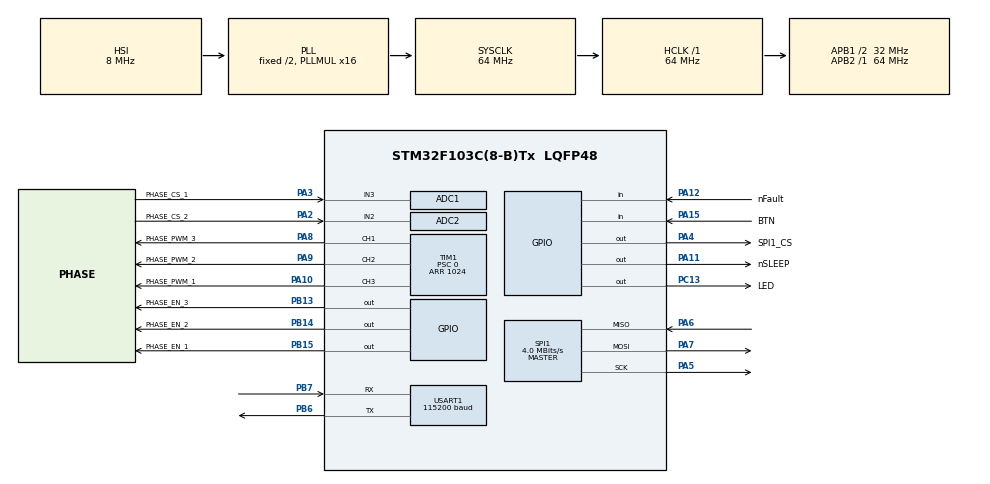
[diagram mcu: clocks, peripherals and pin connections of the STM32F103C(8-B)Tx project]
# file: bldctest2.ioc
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ADC1.Channel-4\#ChannelRegularConversion=ADC_CHANNEL_3
ADC1.Mode=ADC_DUALMODE_REGSIMULT_INJECSIMULT
ADC1.NbrOfConversionFlag=1
ADC1.Rank-4\#ChannelRegularConversion=1
ADC1.SamplingTime-4\#ChannelRegularConversion=ADC_SAMPLETIME_7CYCLES_5
ADC1.master=1
ADC2.Channel-0\#ChannelRegularConversion=ADC_CHANNEL_2
ADC2.Mode=ADC_DUALMODE_REGSIMULT_INJECSIMULT
ADC2.NbrOfConversionFlag=1
ADC2.Rank-0\#ChannelRegularConversion=1
ADC2.SamplingTime-0\#ChannelRegularConversion=ADC_SAMPLETIME_7CYCLES_5
Dma.ADC1.1.Direction=DMA_PERIPH_TO_MEMORY
Dma.ADC1.1.Instance=DMA1_Channel1
Dma.ADC1.1.MemDataAlignment=DMA_MDATAALIGN_WORD
Dma.ADC1.1.MemInc=DMA_MINC_ENABLE
Dma.ADC1.1.Mode=DMA_NORMAL
Dma.ADC1.1.PeriphDataAlignment=DMA_PDATAALIGN_WORD
Dma.ADC1.1.PeriphInc=DMA_PINC_DISABLE
Dma.ADC1.1.Priority=DMA_PRIORITY_LOW
Dma.Request0=USART1_TX
Dma.Request1=ADC1
Dma.USART1_TX.0.Direction=DMA_MEMORY_TO_PERIPH
Dma.USART1_TX.0.Instance=DMA1_Channel4
Dma.USART1_TX.0.MemDataAlignment=DMA_MDATAALIGN_BYTE
Dma.USART1_TX.0.MemInc=DMA_MINC_ENABLE
Dma.USART1_TX.0.Mode=DMA_NORMAL
Dma.USART1_TX.0.PeriphDataAlignment=DMA_PDATAALIGN_BYTE
Dma.USART1_TX.0.PeriphInc=DMA_PINC_DISABLE
Dma.USART1_TX.0.Priority=DMA_PRIORITY_LOW
Mcu.Family=STM32F1
Mcu.Name=STM32F103C(8-B)Tx
Mcu.Package=LQFP48
NVIC.DMA1_Channel1_IRQn=true\:0\:0\:false\:false\:true\:false\:true
NVIC.DMA1_Channel4_IRQn=true\:0\:0\:false\:false\:true\:false\:true
NVIC.PriorityGroup=NVIC_PRIORITYGROUP_4
NVIC.SPI1_IRQn=true\:1\:0\:true\:false\:true\:true\:true
NVIC.TIM1_UP_IRQn=true\:1\:0\:true\:false\:true\:true\:true
PA1.GPIO_Label=PHASE_CS_3
PA1.Signal=ADCx_IN1
PA10.GPIO_Label=PHASE_PWM_1
PA10.Signal=S_TIM1_CH3
PA11.GPIO_Label=nSLEEP
PA11.Signal=GPIO_Output
PA12.GPIO_Label=nFault
PA12.Signal=GPIO_Input
PA13.Mode=Serial_Wire
PA13.Signal=SYS_JTMS-SWDIO
PA14.Mode=Serial_Wire
PA14.Signal=SYS_JTCK-SWCLK
PA15.GPIO_Label=BTN
PA15.GPIO_PuPd=GPIO_PULLUP
PA15.Signal=GPIO_Input
PA2.GPIO_Label=PHASE_CS_2
PA2.Signal=ADCx_IN2
PA3.GPIO_Label=PHASE_CS_1
PA3.Signal=ADCx_IN3
PA4.GPIO_Label=SPI1_CS
PA4.PinState=GPIO_PIN_SET
PA4.Signal=GPIO_Output
PA5.Mode=Full_Duplex_Master
PA5.Signal=SPI1_SCK
PA6.Mode=Full_Duplex_Master
PA6.Signal=SPI1_MISO
PA7.Mode=Full_Duplex_Master
PA7.Signal=SPI1_MOSI
PA8.GPIO_Label=PHASE_PWM_3
PA8.Signal=S_TIM1_CH1
PA9.GPIO_Label=PHASE_PWM_2
PA9.Signal=S_TIM1_CH2
PB1.GPIO_Label=BATT_SENSE
PB1.Signal=ADCx_IN9
PB13.GPIO_Label=PHASE_EN_3
PB13.Signal=GPIO_Output
PB14.GPIO_Label=PHASE_EN_2
PB14.Signal=GPIO_Output
PB15.GPIO_Label=PHASE_EN_1
PB15.Signal=GPIO_Output
PB6.Mode=Asynchronous
PB6.Signal=USART1_TX
PB7.Mode=Asynchronous
PB7.Signal=USART1_RX
PC13-TAMPER-RTC.GPIO_Label=LED
PC13-TAMPER-RTC.PinState=GPIO_PIN_SET
PC13-TAMPER-RTC.Signal=GPIO_Output
ProjectManager.HeapSize=0x200
ProjectManager.StackSize=0x400
ProjectManager.TargetToolchain=STM32CubeIDE
RCC.ADCPresc=RCC_ADCPCLK2_DIV6
RCC.AHBFreq_Value=64000000
RCC.APB1CLKDivider=RCC_HCLK_DIV2
RCC.APB1Freq_Value=32000000
RCC.APB1TimFreq_Value=64000000
RCC.APB2Freq_Value=64000000
RCC.APB2TimFreq_Value=64000000
RCC.HCLKFreq_Value=64000000
RCC.PLLMUL=RCC_PLL_MUL16
RCC.SYSCLKFreq_VALUE=64000000
RCC.SYSCLKSource=RCC_SYSCLKSOURCE_PLLCLK
RCC.USBFreq_Value=64000000
SH.ADCx_IN1.0=ADC1_IN1
SH.ADCx_IN2.0=ADC1_IN2
SH.ADCx_IN2.1=ADC2_IN2,IN2
SH.ADCx_IN3.0=ADC1_IN3,IN3
SH.ADCx_IN9.0=ADC1_IN9
SH.S_TIM1_CH1.0=TIM1_CH1,PWM Generation1 CH1
SH.S_TIM1_CH2.0=TIM1_CH2,PWM Generation2 CH2
SH.S_TIM1_CH3.0=TIM1_CH3,PWM Generation3 CH3
SPI1.BaudRatePrescaler=SPI_BAUDRATEPRESCALER_16
SPI1.CLKPhase=SPI_PHASE_2EDGE
SPI1.CalculateBaudRate=4.0 MBits/s
SPI1.DataSize=SPI_DATASIZE_16BIT
SPI1.Direction=SPI_DIRECTION_2LINES
SPI1.Mode=SPI_MODE_MASTER
SPI1.VirtualType=VM_MASTER
TIM1.AutoReloadPreload=TIM_AUTORELOAD_PRELOAD_ENABLE
TIM1.Channel-PWM\ Generation1\ CH1=TIM_CHANNEL_1
TIM1.Channel-PWM\ Generation2\ CH2=TIM_CHANNEL_2
TIM1.Channel-PWM\ Generation3\ CH3=TIM_CHANNEL_3
TIM1.CounterMode=TIM_COUNTERMODE_CENTERALIGNED2
TIM1.OCIdleState_1=TIM_OCIDLESTATE_RESET
TIM1.OCIdleState_2=TIM_OCIDLESTATE_RESET
TIM1.OCIdleState_3=TIM_OCIDLESTATE_RESET
TIM1.OCMode_PWM-PWM\ Generation1\ CH1=TIM_OCMODE_PWM1
TIM1.OCMode_PWM-PWM\ Generation2\ CH2=TIM_OCMODE_PWM1
TIM1.OCMode_PWM-PWM\ Generation3\ CH3=TIM_OCMODE_PWM1
TIM1.Period=1024
TIM1.Prescaler=0
TIM1.RepetitionCounter=3
TIM3.Period=10
TIM3.Prescaler=225
TIM3.TIM_MasterOutputTrigger=TIM_TRGO_UPDATE
USART1.BaudRate=115200
USART1.Mode=MODE_TX_RX
USART1.VirtualMode=VM_ASYNC
VP_TIM1_VS_ClockSourceINT.Mode=Internal
VP_TIM3_VS_ClockSourceINT.Mode=Internal
board=custom

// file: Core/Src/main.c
/* USER CODE BEGIN Header */
/**
  ******************************************************************************
  * @file           : main.c
  * @brief          : Main program body
  ******************************************************************************
  * @attention
  *
  * <h2><center>&copy; Copyright (c) 2020 STMicroelectronics.
  * All rights reserved.</center></h2>
  *
  * This software component is licensed by ST under BSD 3-Clause license,
  * the "License"; You may not use this file except in compliance with the
  * License. You may obtain a copy of the License at:
  *                        opensource.org/licenses/BSD-3-Clause
  *
  ******************************************************************************
  */
/* USER CODE END Header */

#include "main.h"

/* USER CODE BEGIN Includes */
#include "app/main.hpp"
#include "string.h"
/* USER CODE END Includes */

ADC_HandleTypeDef hadc1;
ADC_HandleTypeDef hadc2;
DMA_HandleTypeDef hdma_adc1;

SPI_HandleTypeDef hspi1;

TIM_HandleTypeDef htim1;
TIM_HandleTypeDef htim3;

UART_HandleTypeDef huart1;
DMA_HandleTypeDef hdma_usart1_tx;

void SystemClock_Config(void);
static void MX_GPIO_Init(void);
static void MX_DMA_Init(void);
static void MX_ADC1_Init(void);
static void MX_SPI1_Init(void);
static void MX_TIM1_Init(void);
static void MX_TIM3_Init(void);
static void MX_USART1_UART_Init(void);
static void MX_ADC2_Init(void);

int main(void)
{

  /* MCU Configuration--------------------------------------------------------*/

  /* Reset of all peripherals, Initializes the Flash interface and the Systick. */
  HAL_Init();

  /* Configure the system clock */
  SystemClock_Config();

  /* Initialize all configured peripherals */
  MX_GPIO_Init();
  MX_DMA_Init();
  MX_ADC1_Init();
  MX_SPI1_Init();
  MX_TIM1_Init();
  MX_TIM3_Init();
  MX_USART1_UART_Init();
  MX_ADC2_Init();
  /* USER CODE BEGIN 2 */
  //const char msg[] = "hello!";

  //__HAL_SPI_ENABLE_IT(&hspi1, SPI_IT_RXNE);

  /* USER CODE END 2 */

  /* Infinite loop */
  /* USER CODE BEGIN WHILE */

  main_cpp();

  while (1)
  {
	/*huart1.Instance->CR3 |= USART_CR3_DMAT;
	HAL_DMA_Start_IT(&hdma_usart1_tx, (uint32_t) &msg, (uint32_t) &huart1.Instance->DR, strlen(msg));

	HAL_Delay(1000);*/
    /* USER CODE END WHILE */

  }
}

void SystemClock_Config(void)
{
  RCC_OscInitTypeDef RCC_OscInitStruct = {0};
  RCC_ClkInitTypeDef RCC_ClkInitStruct = {0};
  RCC_PeriphCLKInitTypeDef PeriphClkInit = {0};

  /** Initializes the CPU, AHB and APB busses clocks
  */
  RCC_OscInitStruct.OscillatorType = RCC_OSCILLATORTYPE_HSI;
  RCC_OscInitStruct.HSIState = RCC_HSI_ON;
  RCC_OscInitStruct.HSICalibrationValue = RCC_HSICALIBRATION_DEFAULT;
  RCC_OscInitStruct.PLL.PLLState = RCC_PLL_ON;
  RCC_OscInitStruct.PLL.PLLSource = RCC_PLLSOURCE_HSI_DIV2;
  RCC_OscInitStruct.PLL.PLLMUL = RCC_PLL_MUL16;
  if (HAL_RCC_OscConfig(&RCC_OscInitStruct) != HAL_OK)
  {
    Error_Handler();
  }
  /** Initializes the CPU, AHB and APB busses clocks
  */
  RCC_ClkInitStruct.ClockType = RCC_CLOCKTYPE_HCLK|RCC_CLOCKTYPE_SYSCLK
                              |RCC_CLOCKTYPE_PCLK1|RCC_CLOCKTYPE_PCLK2;
  RCC_ClkInitStruct.SYSCLKSource = RCC_SYSCLKSOURCE_PLLCLK;
  RCC_ClkInitStruct.AHBCLKDivider = RCC_SYSCLK_DIV1;
  RCC_ClkInitStruct.APB1CLKDivider = RCC_HCLK_DIV2;
  RCC_ClkInitStruct.APB2CLKDivider = RCC_HCLK_DIV1;

  if (HAL_RCC_ClockConfig(&RCC_ClkInitStruct, FLASH_LATENCY_2) != HAL_OK)
  {
    Error_Handler();
  }
  PeriphClkInit.PeriphClockSelection = RCC_PERIPHCLK_ADC;
  PeriphClkInit.AdcClockSelection = RCC_ADCPCLK2_DIV6;
  if (HAL_RCCEx_PeriphCLKConfig(&PeriphClkInit) != HAL_OK)
  {
    Error_Handler();
  }
}

static void MX_ADC1_Init(void)
{

  ADC_MultiModeTypeDef multimode = {0};
  ADC_ChannelConfTypeDef sConfig = {0};

  /** Common config
  */
  hadc1.Instance = ADC1;
  hadc1.Init.ScanConvMode = ADC_SCAN_DISABLE;
  hadc1.Init.ContinuousConvMode = DISABLE;
  hadc1.Init.DiscontinuousConvMode = DISABLE;
  hadc1.Init.ExternalTrigConv = ADC_SOFTWARE_START;
  hadc1.Init.DataAlign = ADC_DATAALIGN_RIGHT;
  hadc1.Init.NbrOfConversion = 1;
  if (HAL_ADC_Init(&hadc1) != HAL_OK)
  {
    Error_Handler();
  }
  /** Configure the ADC multi-mode
  */
  multimode.Mode = ADC_DUALMODE_REGSIMULT_INJECSIMULT;
  if (HAL_ADCEx_MultiModeConfigChannel(&hadc1, &multimode) != HAL_OK)
  {
    Error_Handler();
  }
  /** Configure Regular Channel
  */
  sConfig.Channel = ADC_CHANNEL_3;
  sConfig.Rank = ADC_REGULAR_RANK_1;
  sConfig.SamplingTime = ADC_SAMPLETIME_7CYCLES_5;
  if (HAL_ADC_ConfigChannel(&hadc1, &sConfig) != HAL_OK)
  {
    Error_Handler();
  }
  /* USER CODE BEGIN ADC1_Init 2 */
  while (HAL_ADCEx_Calibration_Start(&hadc1) != HAL_OK);
  /* USER CODE END ADC1_Init 2 */

}

static void MX_ADC2_Init(void)
{

  ADC_ChannelConfTypeDef sConfig = {0};

  /** Common config
  */
  hadc2.Instance = ADC2;
  hadc2.Init.ScanConvMode = ADC_SCAN_DISABLE;
  hadc2.Init.ContinuousConvMode = DISABLE;
  hadc2.Init.DiscontinuousConvMode = DISABLE;
  hadc2.Init.ExternalTrigConv = ADC_SOFTWARE_START;
  hadc2.Init.DataAlign = ADC_DATAALIGN_RIGHT;
  hadc2.Init.NbrOfConversion = 1;
  if (HAL_ADC_Init(&hadc2) != HAL_OK)
  {
    Error_Handler();
  }
  /** Configure Regular Channel
  */
  sConfig.Channel = ADC_CHANNEL_2;
  sConfig.Rank = ADC_REGULAR_RANK_1;
  sConfig.SamplingTime = ADC_SAMPLETIME_7CYCLES_5;
  if (HAL_ADC_ConfigChannel(&hadc2, &sConfig) != HAL_OK)
  {
    Error_Handler();
  }

}

static void MX_SPI1_Init(void)
{

  /* SPI1 parameter configuration*/
  hspi1.Instance = SPI1;
  hspi1.Init.Mode = SPI_MODE_MASTER;
  hspi1.Init.Direction = SPI_DIRECTION_2LINES;
  hspi1.Init.DataSize = SPI_DATASIZE_16BIT;
  hspi1.Init.CLKPolarity = SPI_POLARITY_LOW;
  hspi1.Init.CLKPhase = SPI_PHASE_2EDGE;
  hspi1.Init.NSS = SPI_NSS_SOFT;
  hspi1.Init.BaudRatePrescaler = SPI_BAUDRATEPRESCALER_16;
  hspi1.Init.FirstBit = SPI_FIRSTBIT_MSB;
  hspi1.Init.TIMode = SPI_TIMODE_DISABLE;
  hspi1.Init.CRCCalculation = SPI_CRCCALCULATION_DISABLE;
  hspi1.Init.CRCPolynomial = 10;
  if (HAL_SPI_Init(&hspi1) != HAL_OK)
  {
    Error_Handler();
  }

}

static void MX_TIM1_Init(void)
{

  TIM_ClockConfigTypeDef sClockSourceConfig = {0};
  TIM_MasterConfigTypeDef sMasterConfig = {0};
  TIM_OC_InitTypeDef sConfigOC = {0};
  TIM_BreakDeadTimeConfigTypeDef sBreakDeadTimeConfig = {0};

  htim1.Instance = TIM1;
  htim1.Init.Prescaler = 0;
  htim1.Init.CounterMode = TIM_COUNTERMODE_CENTERALIGNED2;
  htim1.Init.Period = 1024;
  htim1.Init.ClockDivision = TIM_CLOCKDIVISION_DIV1;
  htim1.Init.RepetitionCounter = 3;
  htim1.Init.AutoReloadPreload = TIM_AUTORELOAD_PRELOAD_ENABLE;
  if (HAL_TIM_Base_Init(&htim1) != HAL_OK)
  {
    Error_Handler();
  }
  sClockSourceConfig.ClockSource = TIM_CLOCKSOURCE_INTERNAL;
  if (HAL_TIM_ConfigClockSource(&htim1, &sClockSourceConfig) != HAL_OK)
  {
    Error_Handler();
  }
  if (HAL_TIM_PWM_Init(&htim1) != HAL_OK)
  {
    Error_Handler();
  }
  sMasterConfig.MasterOutputTrigger = TIM_TRGO_RESET;
  sMasterConfig.MasterSlaveMode = TIM_MASTERSLAVEMODE_DISABLE;
  if (HAL_TIMEx_MasterConfigSynchronization(&htim1, &sMasterConfig) != HAL_OK)
  {
    Error_Handler();
  }
  sConfigOC.OCMode = TIM_OCMODE_PWM1;
  sConfigOC.Pulse = 0;
  sConfigOC.OCPolarity = TIM_OCPOLARITY_HIGH;
  sConfigOC.OCNPolarity = TIM_OCNPOLARITY_HIGH;
  sConfigOC.OCFastMode = TIM_OCFAST_DISABLE;
  sConfigOC.OCIdleState = TIM_OCIDLESTATE_RESET;
  sConfigOC.OCNIdleState = TIM_OCNIDLESTATE_RESET;
  if (HAL_TIM_PWM_ConfigChannel(&htim1, &sConfigOC, TIM_CHANNEL_1) != HAL_OK)
  {
    Error_Handler();
  }
  if (HAL_TIM_PWM_ConfigChannel(&htim1, &sConfigOC, TIM_CHANNEL_2) != HAL_OK)
  {
    Error_Handler();
  }
  if (HAL_TIM_PWM_ConfigChannel(&htim1, &sConfigOC, TIM_CHANNEL_3) != HAL_OK)
  {
    Error_Handler();
  }
  sBreakDeadTimeConfig.OffStateRunMode = TIM_OSSR_DISABLE;
  sBreakDeadTimeConfig.OffStateIDLEMode = TIM_OSSI_DISABLE;
  sBreakDeadTimeConfig.LockLevel = TIM_LOCKLEVEL_OFF;
  sBreakDeadTimeConfig.DeadTime = 0;
  sBreakDeadTimeConfig.BreakState = TIM_BREAK_DISABLE;
  sBreakDeadTimeConfig.BreakPolarity = TIM_BREAKPOLARITY_HIGH;
  sBreakDeadTimeConfig.AutomaticOutput = TIM_AUTOMATICOUTPUT_DISABLE;
  if (HAL_TIMEx_ConfigBreakDeadTime(&htim1, &sBreakDeadTimeConfig) != HAL_OK)
  {
    Error_Handler();
  }
  HAL_TIM_MspPostInit(&htim1);

}

static void MX_TIM3_Init(void)
{

  TIM_ClockConfigTypeDef sClockSourceConfig = {0};
  TIM_MasterConfigTypeDef sMasterConfig = {0};

  htim3.Instance = TIM3;
  htim3.Init.Prescaler = 225;
  htim3.Init.CounterMode = TIM_COUNTERMODE_UP;
  htim3.Init.Period = 10;
  htim3.Init.ClockDivision = TIM_CLOCKDIVISION_DIV1;
  htim3.Init.AutoReloadPreload = TIM_AUTORELOAD_PRELOAD_DISABLE;
  if (HAL_TIM_Base_Init(&htim3) != HAL_OK)
  {
    Error_Handler();
  }
  sClockSourceConfig.ClockSource = TIM_CLOCKSOURCE_INTERNAL;
  if (HAL_TIM_ConfigClockSource(&htim3, &sClockSourceConfig) != HAL_OK)
  {
    Error_Handler();
  }
  sMasterConfig.MasterOutputTrigger = TIM_TRGO_UPDATE;
  sMasterConfig.MasterSlaveMode = TIM_MASTERSLAVEMODE_DISABLE;
  if (HAL_TIMEx_MasterConfigSynchronization(&htim3, &sMasterConfig) != HAL_OK)
  {
    Error_Handler();
  }

}

static void MX_USART1_UART_Init(void)
{

  huart1.Instance = USART1;
  huart1.Init.BaudRate = 115200;
  huart1.Init.WordLength = UART_WORDLENGTH_8B;
  huart1.Init.StopBits = UART_STOPBITS_1;
  huart1.Init.Parity = UART_PARITY_NONE;
  huart1.Init.Mode = UART_MODE_TX_RX;
  huart1.Init.HwFlowCtl = UART_HWCONTROL_NONE;
  huart1.Init.OverSampling = UART_OVERSAMPLING_16;
  if (HAL_UART_Init(&huart1) != HAL_OK)
  {
    Error_Handler();
  }

}

static void MX_DMA_Init(void)
{

  /* DMA controller clock enable */
  __HAL_RCC_DMA1_CLK_ENABLE();

  /* DMA interrupt init */
  /* DMA1_Channel1_IRQn interrupt configuration */
  HAL_NVIC_SetPriority(DMA1_Channel1_IRQn, 0, 0);
  HAL_NVIC_EnableIRQ(DMA1_Channel1_IRQn);
  /* DMA1_Channel4_IRQn interrupt configuration */
  HAL_NVIC_SetPriority(DMA1_Channel4_IRQn, 0, 0);
  HAL_NVIC_EnableIRQ(DMA1_Channel4_IRQn);

}

static void MX_GPIO_Init(void)
{
  GPIO_InitTypeDef GPIO_InitStruct = {0};

  /* GPIO Ports Clock Enable */
  __HAL_RCC_GPIOC_CLK_ENABLE();
  __HAL_RCC_GPIOA_CLK_ENABLE();
  __HAL_RCC_GPIOB_CLK_ENABLE();

  /*Configure GPIO pin Output Level */
  HAL_GPIO_WritePin(LED_GPIO_Port, LED_Pin, GPIO_PIN_SET);

  /*Configure GPIO pin Output Level */
  HAL_GPIO_WritePin(SPI1_CS_GPIO_Port, SPI1_CS_Pin, GPIO_PIN_SET);

  /*Configure GPIO pin Output Level */
  HAL_GPIO_WritePin(GPIOB, PHASE_EN_3_Pin|PHASE_EN_2_Pin|PHASE_EN_1_Pin, GPIO_PIN_RESET);

  /*Configure GPIO pin Output Level */
  HAL_GPIO_WritePin(nSLEEP_GPIO_Port, nSLEEP_Pin, GPIO_PIN_RESET);

  /*Configure GPIO pin : LED_Pin */
  GPIO_InitStruct.Pin = LED_Pin;
  GPIO_InitStruct.Mode = GPIO_MODE_OUTPUT_PP;
  GPIO_InitStruct.Pull = GPIO_NOPULL;
  GPIO_InitStruct.Speed = GPIO_SPEED_FREQ_LOW;
  HAL_GPIO_Init(LED_GPIO_Port, &GPIO_InitStruct);

  /*Configure GPIO pins : SPI1_CS_Pin nSLEEP_Pin */
  GPIO_InitStruct.Pin = SPI1_CS_Pin|nSLEEP_Pin;
  GPIO_InitStruct.Mode = GPIO_MODE_OUTPUT_PP;
  GPIO_InitStruct.Pull = GPIO_NOPULL;
  GPIO_InitStruct.Speed = GPIO_SPEED_FREQ_LOW;
  HAL_GPIO_Init(GPIOA, &GPIO_InitStruct);

  /*Configure GPIO pins : PHASE_EN_3_Pin PHASE_EN_2_Pin PHASE_EN_1_Pin */
  GPIO_InitStruct.Pin = PHASE_EN_3_Pin|PHASE_EN_2_Pin|PHASE_EN_1_Pin;
  GPIO_InitStruct.Mode = GPIO_MODE_OUTPUT_PP;
  GPIO_InitStruct.Pull = GPIO_NOPULL;
  GPIO_InitStruct.Speed = GPIO_SPEED_FREQ_LOW;
  HAL_GPIO_Init(GPIOB, &GPIO_InitStruct);

  /*Configure GPIO pin : nFault_Pin */
  GPIO_InitStruct.Pin = nFault_Pin;
  GPIO_InitStruct.Mode = GPIO_MODE_INPUT;
  GPIO_InitStruct.Pull = GPIO_NOPULL;
  HAL_GPIO_Init(nFault_GPIO_Port, &GPIO_InitStruct);

  /*Configure GPIO pin : BTN_Pin */
  GPIO_InitStruct.Pin = BTN_Pin;
  GPIO_InitStruct.Mode = GPIO_MODE_INPUT;
  GPIO_InitStruct.Pull = GPIO_PULLUP;
  HAL_GPIO_Init(BTN_GPIO_Port, &GPIO_InitStruct);

}

void Error_Handler(void)
{
}

/************************ (C) COPYRIGHT STMicroelectronics *****END OF FILE****/
